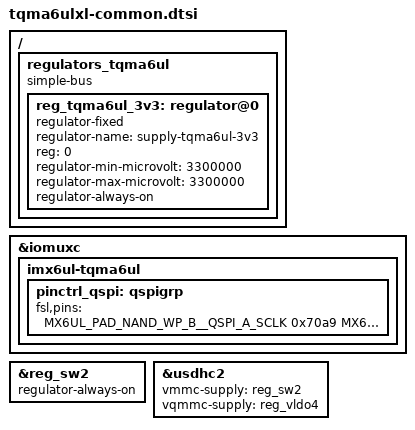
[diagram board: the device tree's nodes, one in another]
/*
 * Copyright 2016 Marco Felsch, TQ Systems GmbH
 * Copyright 2017 - 2018 Markus Niebel, TQ Systems GmbH
 *
 * The code contained herein is licensed under the GNU General Public
 * License. You may obtain a copy of the GNU General Public License
 * Version 2 or later at the following locations:
 *
 * http://www.opensource.org/licenses/gpl-license.html
 * http://www.gnu.org/copyleft/gpl.html
 */

/ {
	regulators_tqma6ul {
		compatible = "simple-bus";
		#address-cells = <1>;
		#size-cells = <0>;

		reg_tqma6ul_3v3: regulator@0 {
			compatible = "regulator-fixed";
			regulator-name = "supply-tqma6ul-3v3";
			reg = <0>;
			regulator-min-microvolt = <3300000>;
			regulator-max-microvolt = <3300000>;
			regulator-always-on;
		};
	};
};

&iomuxc {
	imx6ul-tqma6ul {
		pinctrl_qspi: qspigrp {
			fsl,pins = <
				MX6UL_PAD_NAND_WP_B__QSPI_A_SCLK      0x70a9
				MX6UL_PAD_NAND_READY_B__QSPI_A_DATA00 0x70a9
				MX6UL_PAD_NAND_CE0_B__QSPI_A_DATA01   0x70a9
				MX6UL_PAD_NAND_CE1_B__QSPI_A_DATA02   0x70a9
				MX6UL_PAD_NAND_CLE__QSPI_A_DATA03     0x70a9
				MX6UL_PAD_NAND_DQS__QSPI_A_SS0_B      0x70a1
			>;
		};
	};
};

&reg_sw2 {
	regulator-always-on;
};

/* eMMC */
&usdhc2 {
	vmmc-supply = <&reg_sw2>;
	vqmmc-supply = <&reg_vldo4>;
};
